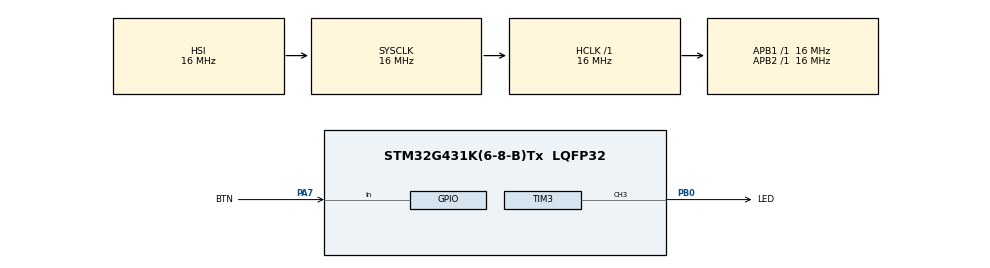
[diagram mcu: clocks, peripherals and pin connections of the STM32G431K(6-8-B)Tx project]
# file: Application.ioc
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Mcu.Family=STM32G4
Mcu.Name=STM32G431K(6-8-B)Tx
Mcu.Package=LQFP32
NVIC.PriorityGroup=NVIC_PRIORITYGROUP_4
PA13.Mode=Serial_Wire
PA13.Signal=SYS_JTMS-SWDIO
PA14.Mode=Serial_Wire
PA14.Signal=SYS_JTCK-SWCLK
PA7.GPIO_Label=BTN
PA7.GPIO_PuPd=GPIO_PULLUP
PA7.Signal=GPIO_Input
PB0.GPIO_Label=LED
PB0.Signal=S_TIM3_CH3
ProjectManager.HeapSize=0x200
ProjectManager.StackSize=0x400
ProjectManager.TargetToolchain=MDK-ARM V5.27
RCC.AHBFreq_Value=16000000
RCC.APB1Freq_Value=16000000
RCC.APB1TimFreq_Value=16000000
RCC.APB2Freq_Value=16000000
RCC.APB2TimFreq_Value=16000000
RCC.CortexFreq_Value=16000000
RCC.EXTERNAL_CLOCK_VALUE=12288000
RCC.HCLKFreq_Value=16000000
RCC.HSE_VALUE=8000000
RCC.HSI48_VALUE=48000000
RCC.HSI_VALUE=16000000
RCC.LSE_VALUE=32768
RCC.PLLM=RCC_PLLM_DIV2
RCC.PLLN=12
RCC.SYSCLKFreq_VALUE=16000000
RCC.USBFreq_Value=48000000
RCC.VCOOutputFreq_Value=96000000
SH.S_TIM3_CH3.0=TIM3_CH3,PWM Generation3 CH3
TIM3.Channel-PWM\ Generation3\ CH3=TIM_CHANNEL_3
TIM3.PeriodNoDither=999
TIM3.Prescaler=0
VP_RTC_VS_RTC_Activate.Mode=RTC_Enabled
VP_SYS_VS_DBSignals.Mode=DisableDeadBatterySignals
board=custom

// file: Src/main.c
/* USER CODE BEGIN Header */
/**
  ******************************************************************************
  * @file           : main.c
  * @brief          : Main program body
  ******************************************************************************
  * @attention
  *
  * <h2><center>&copy; Copyright (c) 2020 STMicroelectronics.
  * All rights reserved.</center></h2>
  *
  * This software component is licensed by ST under BSD 3-Clause license,
  * the "License"; You may not use this file except in compliance with the
  * License. You may obtain a copy of the License at:
  *                        opensource.org/licenses/BSD-3-Clause
  *
  ******************************************************************************
  */
/* USER CODE END Header */

#include "main.h"

RTC_HandleTypeDef hrtc;

TIM_HandleTypeDef htim3;

void SystemClock_Config(void);
static void MX_GPIO_Init(void);
static void MX_RTC_Init(void);
static void MX_TIM3_Init(void);

int main(void)
{
  /* USER CODE BEGIN 1 */
	SCB->VTOR = APP_ADDR;

	uint8_t dir = 0;
	uint16_t count = 0;
  /* USER CODE END 1 */

  /* MCU Configuration--------------------------------------------------------*/

  /* Reset of all peripherals, Initializes the Flash interface and the Systick. */
  HAL_Init();

  /* Configure the system clock */
  SystemClock_Config();

  /* Initialize all configured peripherals */
  MX_GPIO_Init();
  MX_RTC_Init();
  MX_TIM3_Init();

  /* Infinite loop */
  /* USER CODE BEGIN WHILE */
  while (1)
  {
		if (dir == 0)
		{
			if (++count > 998)
			{
				dir = 1;
				HAL_Delay(100);
			}
		}
		else
		{
			if (--count < 2)
			{
				dir = 0;
				HAL_Delay(100);
			}
		}
		__HAL_TIM_SET_COMPARE(&htim3, TIM_CHANNEL_3, count);
		HAL_Delay(1);
    /* USER CODE END WHILE */

  }
}

void SystemClock_Config(void)
{
  RCC_OscInitTypeDef RCC_OscInitStruct = {0};
  RCC_ClkInitTypeDef RCC_ClkInitStruct = {0};
  RCC_PeriphCLKInitTypeDef PeriphClkInit = {0};

  /** Configure the main internal regulator output voltage
  */
  HAL_PWREx_ControlVoltageScaling(PWR_REGULATOR_VOLTAGE_SCALE1);
  /** Initializes the CPU, AHB and APB busses clocks
  */
  RCC_OscInitStruct.OscillatorType = RCC_OSCILLATORTYPE_HSI|RCC_OSCILLATORTYPE_LSI;
  RCC_OscInitStruct.HSIState = RCC_HSI_ON;
  RCC_OscInitStruct.HSICalibrationValue = RCC_HSICALIBRATION_DEFAULT;
  RCC_OscInitStruct.LSIState = RCC_LSI_ON;
  RCC_OscInitStruct.PLL.PLLState = RCC_PLL_NONE;
  if (HAL_RCC_OscConfig(&RCC_OscInitStruct) != HAL_OK)
  {
    Error_Handler();
  }
  /** Initializes the CPU, AHB and APB busses clocks
  */
  RCC_ClkInitStruct.ClockType = RCC_CLOCKTYPE_HCLK|RCC_CLOCKTYPE_SYSCLK
                              |RCC_CLOCKTYPE_PCLK1|RCC_CLOCKTYPE_PCLK2;
  RCC_ClkInitStruct.SYSCLKSource = RCC_SYSCLKSOURCE_HSI;
  RCC_ClkInitStruct.AHBCLKDivider = RCC_SYSCLK_DIV1;
  RCC_ClkInitStruct.APB1CLKDivider = RCC_HCLK_DIV1;
  RCC_ClkInitStruct.APB2CLKDivider = RCC_HCLK_DIV1;

  if (HAL_RCC_ClockConfig(&RCC_ClkInitStruct, FLASH_LATENCY_0) != HAL_OK)
  {
    Error_Handler();
  }
  /** Initializes the peripherals clocks
  */
  PeriphClkInit.PeriphClockSelection = RCC_PERIPHCLK_RTC;
  PeriphClkInit.RTCClockSelection = RCC_RTCCLKSOURCE_LSI;

  if (HAL_RCCEx_PeriphCLKConfig(&PeriphClkInit) != HAL_OK)
  {
    Error_Handler();
  }
}

static void MX_RTC_Init(void)
{

  /** Initialize RTC Only
  */
  hrtc.Instance = RTC;
  hrtc.Init.HourFormat = RTC_HOURFORMAT_24;
  hrtc.Init.AsynchPrediv = 127;
  hrtc.Init.SynchPrediv = 255;
  hrtc.Init.OutPut = RTC_OUTPUT_DISABLE;
  hrtc.Init.OutPutRemap = RTC_OUTPUT_REMAP_NONE;
  hrtc.Init.OutPutPolarity = RTC_OUTPUT_POLARITY_HIGH;
  hrtc.Init.OutPutType = RTC_OUTPUT_TYPE_OPENDRAIN;
  hrtc.Init.OutPutPullUp = RTC_OUTPUT_PULLUP_NONE;
  if (HAL_RTC_Init(&hrtc) != HAL_OK)
  {
    Error_Handler();
  }

}

static void MX_TIM3_Init(void)
{

  TIM_MasterConfigTypeDef sMasterConfig = {0};
  TIM_OC_InitTypeDef sConfigOC = {0};

  /* USER CODE BEGIN TIM3_Init 1 */

	//htim3.Init.Prescaler = 0; defines the pwm frequency, 0=16kHz
	//htim3.Init.Period = 999;  defines the pwm max count

  /* USER CODE END TIM3_Init 1 */
  htim3.Instance = TIM3;

  htim3.Init.CounterMode = TIM_COUNTERMODE_UP;
  htim3.Init.Period = 999;
  htim3.Init.ClockDivision = TIM_CLOCKDIVISION_DIV1;
  htim3.Init.AutoReloadPreload = TIM_AUTORELOAD_PRELOAD_DISABLE;
  if (HAL_TIM_PWM_Init(&htim3) != HAL_OK)
  {
    Error_Handler();
  }
  sMasterConfig.MasterOutputTrigger = TIM_TRGO_RESET;
  sMasterConfig.MasterSlaveMode = TIM_MASTERSLAVEMODE_DISABLE;
  if (HAL_TIMEx_MasterConfigSynchronization(&htim3, &sMasterConfig) != HAL_OK)
  {
    Error_Handler();
  }
  sConfigOC.OCMode = TIM_OCMODE_PWM1;
  sConfigOC.Pulse = 0;
  sConfigOC.OCPolarity = TIM_OCPOLARITY_HIGH;
  sConfigOC.OCFastMode = TIM_OCFAST_DISABLE;
  if (HAL_TIM_PWM_ConfigChannel(&htim3, &sConfigOC, TIM_CHANNEL_3) != HAL_OK)
  {
    Error_Handler();
  }
  /* USER CODE BEGIN TIM3_Init 2 */
	HAL_TIM_PWM_Start(&htim3, TIM_CHANNEL_3);
  /* USER CODE END TIM3_Init 2 */
  HAL_TIM_MspPostInit(&htim3);

}

static void MX_GPIO_Init(void)
{
  GPIO_InitTypeDef GPIO_InitStruct = {0};

  /* GPIO Ports Clock Enable */
  __HAL_RCC_GPIOA_CLK_ENABLE();
  __HAL_RCC_GPIOB_CLK_ENABLE();

  /*Configure GPIO pin : BTN_Pin */
  GPIO_InitStruct.Pin = BTN_Pin;
  GPIO_InitStruct.Mode = GPIO_MODE_INPUT;
  GPIO_InitStruct.Pull = GPIO_PULLUP;
  HAL_GPIO_Init(BTN_GPIO_Port, &GPIO_InitStruct);

}

void Error_Handler(void)
{
}

/************************ (C) COPYRIGHT STMicroelectronics *****END OF FILE****/
